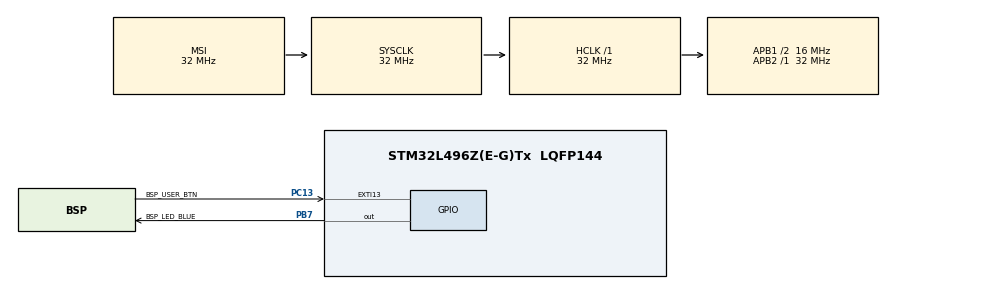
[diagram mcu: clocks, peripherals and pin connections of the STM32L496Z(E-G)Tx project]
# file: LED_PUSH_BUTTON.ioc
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Mcu.Family=STM32L4
Mcu.Name=STM32L496Z(E-G)Tx
Mcu.Package=LQFP144
NVIC.EXTI15_10_IRQn=true\:0\:0\:false\:false\:true\:true\:true\:true
NVIC.PriorityGroup=NVIC_PRIORITYGROUP_4
PA13\ (JTMS/SWDIO).Mode=Serial_Wire
PA13\ (JTMS/SWDIO).Signal=SYS_JTMS-SWDIO
PA14\ (JTCK/SWCLK).Mode=Serial_Wire
PA14\ (JTCK/SWCLK).Signal=SYS_JTCK-SWCLK
PB7.GPIO_Label=BSP_LED_BLUE
PB7.Signal=GPIO_Output
PC13.GPIO_Label=BSP_USER_BTN
PC13.Signal=GPXTI13
PH0-OSC_IN\ (PH0).Mode=HSE-External-Oscillator
PH0-OSC_IN\ (PH0).Signal=RCC_OSC_IN
PH1-OSC_OUT\ (PH1).Mode=HSE-External-Oscillator
PH1-OSC_OUT\ (PH1).Signal=RCC_OSC_OUT
ProjectManager.HeapSize=0x200
ProjectManager.StackSize=0x400
ProjectManager.TargetToolchain=STM32CubeIDE
RCC.48MHZClocksFreq_Value=24000000
RCC.ADCFreq_Value=384000000
RCC.AHBFreq_Value=32000000
RCC.APB1CLKDivider=RCC_HCLK_DIV2
RCC.APB1Freq_Value=16000000
RCC.APB1TimFreq_Value=32000000
RCC.APB2Freq_Value=32000000
RCC.APB2TimFreq_Value=32000000
RCC.CortexFreq_Value=32000000
RCC.HCLKFreq_Value=32000000
RCC.HSE_VALUE=8000000
RCC.HSI48_VALUE=48000000
RCC.HSI_VALUE=16000000
RCC.MSIClockRange=RCC_MSIRANGE_10
RCC.MSI_VALUE=32000000
RCC.PLLMUL=RCC_PLL_MUL9
RCC.PLLSAI1N=24
RCC.PRESCALERUSB=RCC_USBCLKSOURCE_PLL_DIV1_5
RCC.SYSCLKFreq_VALUE=32000000
RCC.SYSCLKSourceVirtual=RCC_SYSCLKSOURCE_PLLCLK
RCC.USBFreq_Value=384000000
RCC.VCOOutputFreq_Value=256000000
board=NUCLEO-L496ZG

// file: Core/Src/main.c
/* USER CODE BEGIN Header */
/**
  ******************************************************************************
  * @file           : main.c
  * @brief          : Main program body
  ******************************************************************************
  * @attention
  *
  * Copyright (c) 2023 STMicroelectronics.
  * All rights reserved.
  *
  * This software is licensed under terms that can be found in the LICENSE file
  * in the root directory of this software component.
  * If no LICENSE file comes with this software, it is provided AS-IS.
  *
  ******************************************************************************
  */
/* USER CODE END Header */
#include "main.h"

void SystemClock_Config(void);
static void MX_GPIO_Init(void);
/* USER CODE BEGIN PFP */
uint8_t modeSelection = 0;
/* USER CODE END PFP */

int main(void)
{

  /* MCU Configuration--------------------------------------------------------*/

  /* Reset of all peripherals, Initializes the Flash interface and the Systick. */
  HAL_Init();

  /* Configure the system clock */
  SystemClock_Config();

  /* Initialize all configured peripherals */
  MX_GPIO_Init();

  /* Infinite loop */
  while (1)
  {

  }
}

void SystemClock_Config(void)
{
  RCC_OscInitTypeDef RCC_OscInitStruct = {0};
  RCC_ClkInitTypeDef RCC_ClkInitStruct = {0};

  /** Configure the main internal regulator output voltage
  */
  if (HAL_PWREx_ControlVoltageScaling(PWR_REGULATOR_VOLTAGE_SCALE1) != HAL_OK)
  {
    Error_Handler();
  }

  /** Initializes the RCC Oscillators according to the specified parameters
  * in the RCC_OscInitTypeDef structure.
  */
  RCC_OscInitStruct.OscillatorType = RCC_OSCILLATORTYPE_MSI;
  RCC_OscInitStruct.MSIState = RCC_MSI_ON;
  RCC_OscInitStruct.MSICalibrationValue = 0;
  RCC_OscInitStruct.MSIClockRange = RCC_MSIRANGE_10;
  RCC_OscInitStruct.PLL.PLLState = RCC_PLL_NONE;
  if (HAL_RCC_OscConfig(&RCC_OscInitStruct) != HAL_OK)
  {
    Error_Handler();
  }

  /** Initializes the CPU, AHB and APB buses clocks
  */
  RCC_ClkInitStruct.ClockType = RCC_CLOCKTYPE_HCLK|RCC_CLOCKTYPE_SYSCLK
                              |RCC_CLOCKTYPE_PCLK1|RCC_CLOCKTYPE_PCLK2;
  RCC_ClkInitStruct.SYSCLKSource = RCC_SYSCLKSOURCE_MSI;
  RCC_ClkInitStruct.AHBCLKDivider = RCC_SYSCLK_DIV1;
  RCC_ClkInitStruct.APB1CLKDivider = RCC_HCLK_DIV2;
  RCC_ClkInitStruct.APB2CLKDivider = RCC_HCLK_DIV1;

  if (HAL_RCC_ClockConfig(&RCC_ClkInitStruct, FLASH_LATENCY_1) != HAL_OK)
  {
    Error_Handler();
  }
}

static void MX_GPIO_Init(void)
{
  GPIO_InitTypeDef GPIO_InitStruct = {0};

  /* GPIO Ports Clock Enable */
  __HAL_RCC_GPIOC_CLK_ENABLE();
  __HAL_RCC_GPIOH_CLK_ENABLE();
  __HAL_RCC_GPIOA_CLK_ENABLE();
  __HAL_RCC_GPIOB_CLK_ENABLE();

  /*Configure GPIO pin Output Level */
  HAL_GPIO_WritePin(BSP_LED_BLUE_GPIO_Port, BSP_LED_BLUE_Pin, GPIO_PIN_RESET);

  /*Configure GPIO pin : BSP_USER_BTN_Pin */
  GPIO_InitStruct.Pin = BSP_USER_BTN_Pin;
  GPIO_InitStruct.Mode = GPIO_MODE_IT_RISING;
  GPIO_InitStruct.Pull = GPIO_NOPULL;
  HAL_GPIO_Init(BSP_USER_BTN_GPIO_Port, &GPIO_InitStruct);

  /*Configure GPIO pin : BSP_LED_BLUE_Pin */
  GPIO_InitStruct.Pin = BSP_LED_BLUE_Pin;
  GPIO_InitStruct.Mode = GPIO_MODE_OUTPUT_PP;
  GPIO_InitStruct.Pull = GPIO_NOPULL;
  GPIO_InitStruct.Speed = GPIO_SPEED_FREQ_LOW;
  HAL_GPIO_Init(BSP_LED_BLUE_GPIO_Port, &GPIO_InitStruct);

  /* EXTI interrupt init*/
  HAL_NVIC_SetPriority(EXTI15_10_IRQn, 0, 0);
  HAL_NVIC_EnableIRQ(EXTI15_10_IRQn);

}

/* USER CODE BEGIN 4 */
void HAL_GPIO_EXTI_Callback(uint16_t GPIO_Pin)

{
	if (GPIO_Pin == BSP_USER_BTN_Pin) // Replace 'y' with the specific button pin number
	//  if(modeSelection = 1)
		{
	        // Turn on the LED
	      //  HAL_GPIO_WritePin(BSP_LED_BLUE_GPIO_Port,BSP_LED_BLUE_Pin, GPIO_PIN_SET); // Replace 'GPIOx' with the appropriate GPIO port
	    HAL_GPIO_TogglePin(BSP_LED_BLUE_GPIO_Port,BSP_LED_BLUE_Pin);
		}
	else
	{
		HAL_GPIO_WritePin(BSP_LED_BLUE_GPIO_Port,BSP_LED_BLUE_Pin, GPIO_PIN_RESET);
	}

}
/* USER CODE END 4 */

void Error_Handler(void)
{
  __disable_irq();
  while (1)
  {
  }
}
